# DDR16SS_DDR16SS_CTLPHY_WRAP_CTL_CFG_CTLCFG_0F308000h register map
Vendor: Texas Instruments
Registers are 32-bit, read-write, reset 0x0 unless marked. A register's access mark holds for its fields unless they carry their own. Offsets are as the file gives them; [hi:lo] are bit positions; lines under a group give offsets from that group; {n}, {i} and the like mark numbered series.

## DDR16SS_CTLPHY_WRAP_CTL_CFG_CTLCFG (part 7 of 11)
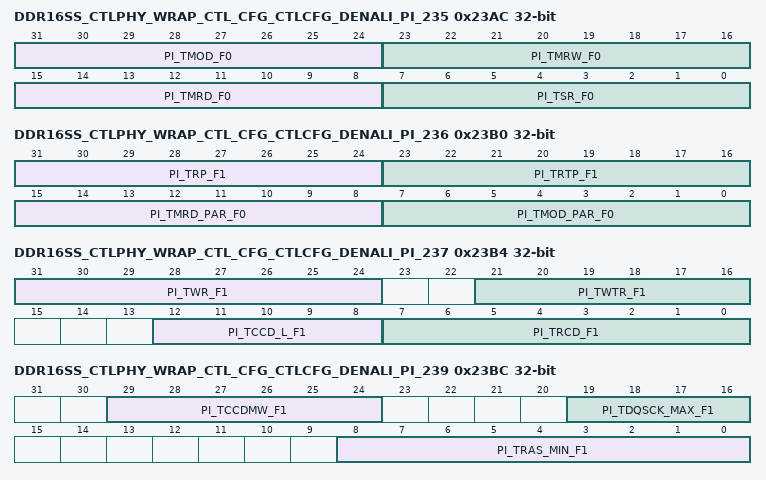
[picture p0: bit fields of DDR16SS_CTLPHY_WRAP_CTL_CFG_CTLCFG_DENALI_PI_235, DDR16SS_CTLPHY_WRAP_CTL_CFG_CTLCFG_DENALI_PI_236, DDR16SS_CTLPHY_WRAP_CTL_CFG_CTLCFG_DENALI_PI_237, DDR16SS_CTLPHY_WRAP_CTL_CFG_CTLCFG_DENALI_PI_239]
0x23AC DDR16SS_CTLPHY_WRAP_CTL_CFG_CTLCFG_DENALI_PI_235
  [31:24] PI_TMOD_F0 — DRAM tMOD value in cycles for frequency set 0. Reset Source: ctl_amod_g_rst_n
  [23:16] PI_TMRW_F0 — DRAM tMRW value in cycles for frequency set 0. Reset Source: ctl_amod_g_rst_n
  [15:8] PI_TMRD_F0 — DRAM tMRD value in cycles for frequency set 0. Reset Source: ctl_amod_g_rst_n
  [7:0] PI_TSR_F0 — Min cycles from sref entry to sref exit for frequency set 0. Reset Source: ctl_amod_g_rst_n
0x23B0 DDR16SS_CTLPHY_WRAP_CTL_CFG_CTLCFG_DENALI_PI_236
  [31:24] PI_TRP_F1 — DRAM tRP value in cycles for frequency set 1. Reset Source: ctl_amod_g_rst_n
  [23:16] PI_TRTP_F1 — DRAM tRTP value in cycles for frequency set 1. Reset Source: ctl_amod_g_rst_n
  [15:8] PI_TMRD_PAR_F0 — DRAM tMRD value when CA parity is enabled in cycles for frequency set 0. Reset Source: ctl_amod_g_rst_n
  [7:0] PI_TMOD_PAR_F0 — DRAM tMOD value when CA parity is enabled in cycles for frequency set 0. Reset Source: ctl_amod_g_rst_n
0x23B4 DDR16SS_CTLPHY_WRAP_CTL_CFG_CTLCFG_DENALI_PI_237
  [31:24] PI_TWR_F1 — DRAM tWR value in cycles for frequency set 1. Reset Source: ctl_amod_g_rst_n
  [21:16] PI_TWTR_F1 — DRAM tWTR value in cycles for frequency set 1. Reset Source: ctl_amod_g_rst_n
  [12:8] PI_TCCD_L_F1 — DRAM CAS-to_CAS value within the same bank group in cycles for frequency set 1. Reset Source: ctl_amod_g_rst_n
  [7:0] PI_TRCD_F1 — DRAM tRCD value in cycles for frequency set 1. Reset Source: ctl_amod_g_rst_n
0x23B8 DDR16SS_CTLPHY_WRAP_CTL_CFG_CTLCFG_DENALI_PI_238
  [19:0] PI_TRAS_MAX_F1 — DRAM tRAS_MAX value in cycles for frequency set 1. Reset Source: ctl_amod_g_rst_n
0x23BC DDR16SS_CTLPHY_WRAP_CTL_CFG_CTLCFG_DENALI_PI_239
  [29:24] PI_TCCDMW_F1 — LPDDR4 DRAM tCCDMW in cycles for frequency set 1. Reset Source: ctl_amod_g_rst_n
  [19:16] PI_TDQSCK_MAX_F1 — Additional delay needed for tDQSCK for frequency set 1. Reset Source: ctl_amod_g_rst_n
  [8:0] PI_TRAS_MIN_F1 — DRAM tRAS_MIN value in cycles for frequency set 1. Reset Source: ctl_amod_g_rst_n
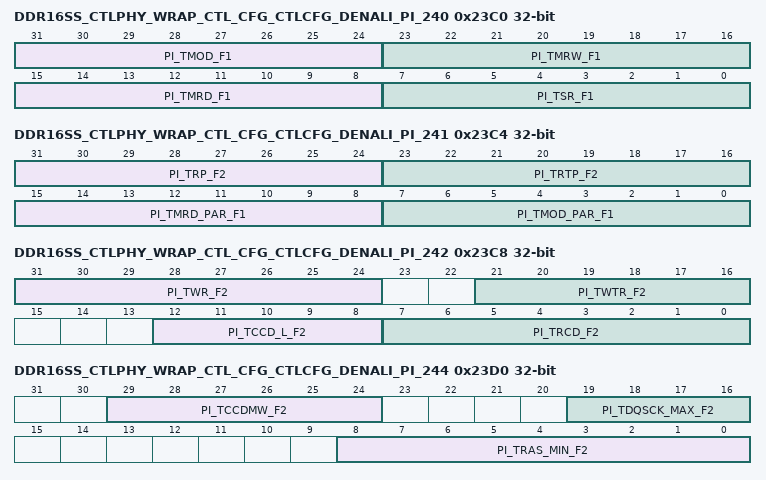
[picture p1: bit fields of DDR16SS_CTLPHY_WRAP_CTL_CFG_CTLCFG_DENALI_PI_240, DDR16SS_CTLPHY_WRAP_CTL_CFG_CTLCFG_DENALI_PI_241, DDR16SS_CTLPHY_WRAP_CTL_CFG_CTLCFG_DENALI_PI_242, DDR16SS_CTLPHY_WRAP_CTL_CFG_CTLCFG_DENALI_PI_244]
0x23C0 DDR16SS_CTLPHY_WRAP_CTL_CFG_CTLCFG_DENALI_PI_240
  [31:24] PI_TMOD_F1 — DRAM tMOD value in cycles for frequency set 1. Reset Source: ctl_amod_g_rst_n
  [23:16] PI_TMRW_F1 — DRAM tMRW value in cycles for frequency set 1. Reset Source: ctl_amod_g_rst_n
  [15:8] PI_TMRD_F1 — DRAM tMRD value in cycles for frequency set 1. Reset Source: ctl_amod_g_rst_n
  [7:0] PI_TSR_F1 — Min cycles from sref entry to sref exit for frequency set 1. Reset Source: ctl_amod_g_rst_n
0x23C4 DDR16SS_CTLPHY_WRAP_CTL_CFG_CTLCFG_DENALI_PI_241
  [31:24] PI_TRP_F2 — DRAM tRP value in cycles for frequency set 2. Reset Source: ctl_amod_g_rst_n
  [23:16] PI_TRTP_F2 — DRAM tRTP value in cycles for frequency set 2. Reset Source: ctl_amod_g_rst_n
  [15:8] PI_TMRD_PAR_F1 — DRAM tMRD value when CA parity is enabled in cycles for frequency set 1. Reset Source: ctl_amod_g_rst_n
  [7:0] PI_TMOD_PAR_F1 — DRAM tMOD value when CA parity is enabled in cycles for frequency set 1. Reset Source: ctl_amod_g_rst_n
0x23C8 DDR16SS_CTLPHY_WRAP_CTL_CFG_CTLCFG_DENALI_PI_242
  [31:24] PI_TWR_F2 — DRAM tWR value in cycles for frequency set 2. Reset Source: ctl_amod_g_rst_n
  [21:16] PI_TWTR_F2 — DRAM tWTR value in cycles for frequency set 2. Reset Source: ctl_amod_g_rst_n
  [12:8] PI_TCCD_L_F2 — DRAM CAS-to_CAS value within the same bank group in cycles for frequency set 2. Reset Source: ctl_amod_g_rst_n
  [7:0] PI_TRCD_F2 — DRAM tRCD value in cycles for frequency set 2. Reset Source: ctl_amod_g_rst_n
0x23CC DDR16SS_CTLPHY_WRAP_CTL_CFG_CTLCFG_DENALI_PI_243
  [19:0] PI_TRAS_MAX_F2 — DRAM tRAS_MAX value in cycles for frequency set 2. Reset Source: ctl_amod_g_rst_n
0x23D0 DDR16SS_CTLPHY_WRAP_CTL_CFG_CTLCFG_DENALI_PI_244
  [29:24] PI_TCCDMW_F2 — LPDDR4 DRAM tCCDMW in cycles for frequency set 2. Reset Source: ctl_amod_g_rst_n
  [19:16] PI_TDQSCK_MAX_F2 — Additional delay needed for tDQSCK for frequency set 2. Reset Source: ctl_amod_g_rst_n
  [8:0] PI_TRAS_MIN_F2 — DRAM tRAS_MIN value in cycles for frequency set 2. Reset Source: ctl_amod_g_rst_n
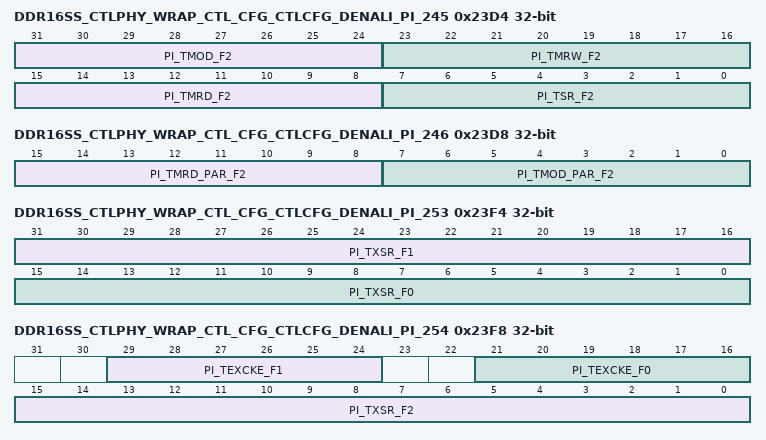
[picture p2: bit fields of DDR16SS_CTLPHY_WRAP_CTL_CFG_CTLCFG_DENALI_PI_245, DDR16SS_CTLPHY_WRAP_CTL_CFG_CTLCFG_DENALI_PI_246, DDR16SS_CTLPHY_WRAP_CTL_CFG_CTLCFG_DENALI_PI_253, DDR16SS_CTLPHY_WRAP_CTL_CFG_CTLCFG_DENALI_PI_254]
0x23D4 DDR16SS_CTLPHY_WRAP_CTL_CFG_CTLCFG_DENALI_PI_245
  [31:24] PI_TMOD_F2 — DRAM tMOD value in cycles for frequency set 2. Reset Source: ctl_amod_g_rst_n
  [23:16] PI_TMRW_F2 — DRAM tMRW value in cycles for frequency set 2. Reset Source: ctl_amod_g_rst_n
  [15:8] PI_TMRD_F2 — DRAM tMRD value in cycles for frequency set 2. Reset Source: ctl_amod_g_rst_n
  [7:0] PI_TSR_F2 — Min cycles from sref entry to sref exit for frequency set 2. Reset Source: ctl_amod_g_rst_n
0x23D8 DDR16SS_CTLPHY_WRAP_CTL_CFG_CTLCFG_DENALI_PI_246
  [15:8] PI_TMRD_PAR_F2 — DRAM tMRD value when CA parity is enabled in cycles for frequency set 2. Reset Source: ctl_amod_g_rst_n
  [7:0] PI_TMOD_PAR_F2 — DRAM tMOD value when CA parity is enabled in cycles for frequency set 2. Reset Source: ctl_amod_g_rst_n
0x23DC DDR16SS_CTLPHY_WRAP_CTL_CFG_CTLCFG_DENALI_PI_247
  [20:0] PI_TDFI_CTRLUPD_MAX_F0 — Defines the DFI tCTRLUPD_MAX timing parameter [in DFI clocks] for frequency set 0, the maximum cycles that dfi_ctrlupd_req can be asserted. If programmed to a non-zero, a timing violation will cause an interrupt and bit [1] set in the PI_UPDATE_ERROR_STATUS parameter. Reset Source: ctl_amod_g_rst_n
0x23E0 DDR16SS_CTLPHY_WRAP_CTL_CFG_CTLCFG_DENALI_PI_248
  [31:0] PI_TDFI_CTRLUPD_INTERVAL_F0 — Defines the DFI tCTRLUPD_INTERVAL timing parameter [in DFI clocks] for frequency set 0, the maximum cycles between dfi_ctrlupd_req assertions. If programmed to a non-zero, a timing violation will cause an interrupt and bit [0] set in the PI_UPDATE_ERROR_STATUS parameter. Reset Source: ctl_amod_g_rst_n
0x23E4 DDR16SS_CTLPHY_WRAP_CTL_CFG_CTLCFG_DENALI_PI_249
  [20:0] PI_TDFI_CTRLUPD_MAX_F1 — Defines the DFI tCTRLUPD_MAX timing parameter [in DFI clocks] for frequency set 1, the maximum cycles that dfi_ctrlupd_req can be asserted. If programmed to a non-zero, a timing violation will cause an interrupt and bit [1] set in the PI_UPDATE_ERROR_STATUS parameter. Reset Source: ctl_amod_g_rst_n
0x23E8 DDR16SS_CTLPHY_WRAP_CTL_CFG_CTLCFG_DENALI_PI_250
  [31:0] PI_TDFI_CTRLUPD_INTERVAL_F1 — Defines the DFI tCTRLUPD_INTERVAL timing parameter [in DFI clocks] for frequency set 1, the maximum cycles between dfi_ctrlupd_req assertions. If programmed to a non-zero, a timing violation will cause an interrupt and bit [0] set in the PI_UPDATE_ERROR_STATUS parameter. Reset Source: ctl_amod_g_rst_n
0x23EC DDR16SS_CTLPHY_WRAP_CTL_CFG_CTLCFG_DENALI_PI_251
  [20:0] PI_TDFI_CTRLUPD_MAX_F2 — Defines the DFI tCTRLUPD_MAX timing parameter [in DFI clocks] for frequency set 2, the maximum cycles that dfi_ctrlupd_req can be asserted. If programmed to a non-zero, a timing violation will cause an interrupt and bit [1] set in the PI_UPDATE_ERROR_STATUS parameter. Reset Source: ctl_amod_g_rst_n
0x23F0 DDR16SS_CTLPHY_WRAP_CTL_CFG_CTLCFG_DENALI_PI_252
  [31:0] PI_TDFI_CTRLUPD_INTERVAL_F2 — Defines the DFI tCTRLUPD_INTERVAL timing parameter [in DFI clocks] for frequency set 2, the maximum cycles between dfi_ctrlupd_req assertions. If programmed to a non-zero, a timing violation will cause an interrupt and bit [0] set in the PI_UPDATE_ERROR_STATUS parameter. Reset Source: ctl_amod_g_rst_n
0x23F4 DDR16SS_CTLPHY_WRAP_CTL_CFG_CTLCFG_DENALI_PI_253
  [31:16] PI_TXSR_F1 — DRAM TXSR value for frequency set 1 in cycles. Reset Source: ctl_amod_g_rst_n
  [15:0] PI_TXSR_F0 — DRAM TXSR value for frequency set 0 in cycles. Reset Source: ctl_amod_g_rst_n
0x23F8 DDR16SS_CTLPHY_WRAP_CTL_CFG_CTLCFG_DENALI_PI_254
  [29:24] PI_TEXCKE_F1 — DRAM CKE low after SREF command timing for frequency set 1. Reset Source: ctl_amod_g_rst_n
  [21:16] PI_TEXCKE_F0 — DRAM CKE low after SREF command timing for frequency set 0. Reset Source: ctl_amod_g_rst_n
  [15:0] PI_TXSR_F2 — DRAM TXSR value for frequency set 2 in cycles. Reset Source: ctl_amod_g_rst_n
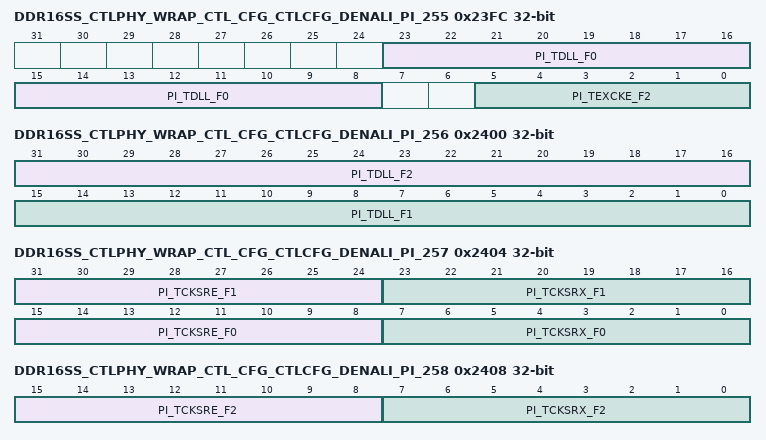
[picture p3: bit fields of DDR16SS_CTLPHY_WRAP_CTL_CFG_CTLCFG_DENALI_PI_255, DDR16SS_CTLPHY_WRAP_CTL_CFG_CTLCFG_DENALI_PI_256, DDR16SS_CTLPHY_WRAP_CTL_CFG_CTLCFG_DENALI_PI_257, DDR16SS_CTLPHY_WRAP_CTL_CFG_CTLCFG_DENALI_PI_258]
0x23FC DDR16SS_CTLPHY_WRAP_CTL_CFG_CTLCFG_DENALI_PI_255
  [23:8] PI_TDLL_F0 — DRAM tDLL value for frequency set 0 in cycles. Reset Source: ctl_amod_g_rst_n
  [5:0] PI_TEXCKE_F2 — DRAM CKE low after SREF command timing for frequency set 2. Reset Source: ctl_amod_g_rst_n
0x2400 DDR16SS_CTLPHY_WRAP_CTL_CFG_CTLCFG_DENALI_PI_256
  [31:16] PI_TDLL_F2 — DRAM tDLL value for frequency set 2 in cycles. Reset Source: ctl_amod_g_rst_n
  [15:0] PI_TDLL_F1 — DRAM tDLL value for frequency set 1 in cycles. Reset Source: ctl_amod_g_rst_n
0x2404 DDR16SS_CTLPHY_WRAP_CTL_CFG_CTLCFG_DENALI_PI_257
  [31:24] PI_TCKSRE_F1 — DRAM tCKSRE value. Reset Source: ctl_amod_g_rst_n
  [23:16] PI_TCKSRX_F1 — DRAM tCKSRX value. Reset Source: ctl_amod_g_rst_n
  [15:8] PI_TCKSRE_F0 — DRAM tCKSRE value. Reset Source: ctl_amod_g_rst_n
  [7:0] PI_TCKSRX_F0 — DRAM tCKSRX value. Reset Source: ctl_amod_g_rst_n
0x2408 DDR16SS_CTLPHY_WRAP_CTL_CFG_CTLCFG_DENALI_PI_258
  [15:8] PI_TCKSRE_F2 — DRAM tCKSRE value. Reset Source: ctl_amod_g_rst_n
  [7:0] PI_TCKSRX_F2 — DRAM tCKSRX value. Reset Source: ctl_amod_g_rst_n
0x240C DDR16SS_CTLPHY_WRAP_CTL_CFG_CTLCFG_DENALI_PI_259
  [23:0] PI_TINIT_F0 — DRAM tINIT value for frequency set 0 in cycles. Reset Source: ctl_amod_g_rst_n
{0x2000+4i} DDR16SS_CTLPHY_WRAP_CTL_CFG_CTLCFG_DENALI_PI_{i} (i=260..262)
  [23:0] PI_TINIT{i-257}_F0 — DRAM tINIT{i-257} value for frequency set 0 in cycles. Reset Source: ctl_amod_g_rst_n
0x241C DDR16SS_CTLPHY_WRAP_CTL_CFG_CTLCFG_DENALI_PI_263
  [15:0] PI_TXSNR_F0 — DRAM tXSNR value for frequency set 0 in cycles. Reset Source: ctl_amod_g_rst_n
0x2420 DDR16SS_CTLPHY_WRAP_CTL_CFG_CTLCFG_DENALI_PI_264
  [23:0] PI_TINIT_F1 — DRAM tINIT value for frequency set 1 in cycles. Reset Source: ctl_amod_g_rst_n
{0x2000+4i} DDR16SS_CTLPHY_WRAP_CTL_CFG_CTLCFG_DENALI_PI_{i} (i=265..267)
  [23:0] PI_TINIT{i-262}_F1 — DRAM tINIT{i-262} value for frequency set 1 in cycles. Reset Source: ctl_amod_g_rst_n
0x2430 DDR16SS_CTLPHY_WRAP_CTL_CFG_CTLCFG_DENALI_PI_268
  [15:0] PI_TXSNR_F1 — DRAM tXSNR value for frequency set 1 in cycles. Reset Source: ctl_amod_g_rst_n
0x2434 DDR16SS_CTLPHY_WRAP_CTL_CFG_CTLCFG_DENALI_PI_269
  [23:0] PI_TINIT_F2 — DRAM tINIT value for frequency set 2 in cycles. Reset Source: ctl_amod_g_rst_n
{0x2000+4i} DDR16SS_CTLPHY_WRAP_CTL_CFG_CTLCFG_DENALI_PI_{i} (i=270..272)
  [23:0] PI_TINIT{i-267}_F2 — DRAM tINIT{i-267} value for frequency set 2 in cycles. Reset Source: ctl_amod_g_rst_n
0x2444 DDR16SS_CTLPHY_WRAP_CTL_CFG_CTLCFG_DENALI_PI_273
  [15:0] PI_TXSNR_F2 — DRAM tXSNR value for frequency set 2 in cycles. Reset Source: ctl_amod_g_rst_n
0x2448 DDR16SS_CTLPHY_WRAP_CTL_CFG_CTLCFG_DENALI_PI_274
  [27:16] PI_TZQCAL_F0 — Holds the DRAM ZQCAL value for frequency set 0 in cycles. Reset Source: ctl_amod_g_rst_n
0x244C DDR16SS_CTLPHY_WRAP_CTL_CFG_CTLCFG_DENALI_PI_275
  [6:0] PI_TZQLAT_F0 — Holds the DRAM ZQLAT value for frequency set 0 in cycles. Reset Source: ctl_amod_g_rst_n
0x2450 DDR16SS_CTLPHY_WRAP_CTL_CFG_CTLCFG_DENALI_PI_276
  [27:16] PI_TZQCAL_F1 — Holds the DRAM ZQCAL value for frequency set 1 in cycles. Reset Source: ctl_amod_g_rst_n
0x2454 DDR16SS_CTLPHY_WRAP_CTL_CFG_CTLCFG_DENALI_PI_277
  [6:0] PI_TZQLAT_F1 — Holds the DRAM ZQLAT value for frequency set 1 in cycles. Reset Source: ctl_amod_g_rst_n
0x2458 DDR16SS_CTLPHY_WRAP_CTL_CFG_CTLCFG_DENALI_PI_278
  [27:16] PI_TZQCAL_F2 — Holds the DRAM ZQCAL value for frequency set 2 in cycles. Reset Source: ctl_amod_g_rst_n
0x245C DDR16SS_CTLPHY_WRAP_CTL_CFG_CTLCFG_DENALI_PI_279
  [6:0] PI_TZQLAT_F2 — Holds the DRAM ZQLAT value for frequency set 2 in cycles. Reset Source: ctl_amod_g_rst_n
0x2460 DDR16SS_CTLPHY_WRAP_CTL_CFG_CTLCFG_DENALI_PI_280 access not given reset not defined
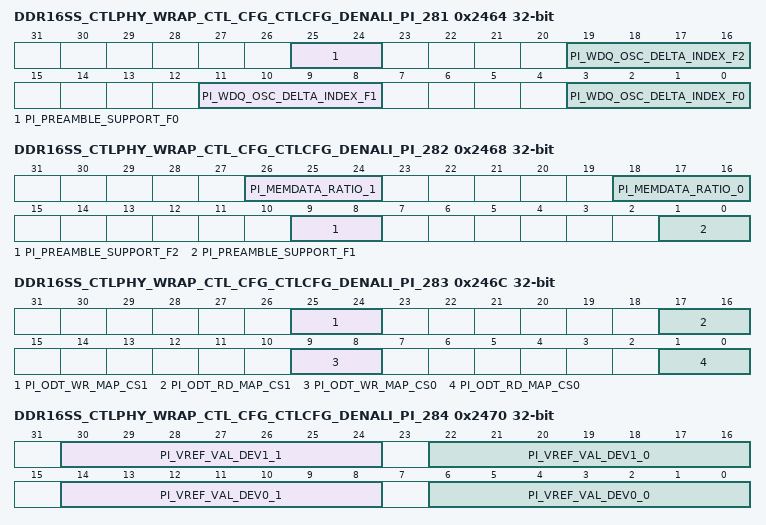
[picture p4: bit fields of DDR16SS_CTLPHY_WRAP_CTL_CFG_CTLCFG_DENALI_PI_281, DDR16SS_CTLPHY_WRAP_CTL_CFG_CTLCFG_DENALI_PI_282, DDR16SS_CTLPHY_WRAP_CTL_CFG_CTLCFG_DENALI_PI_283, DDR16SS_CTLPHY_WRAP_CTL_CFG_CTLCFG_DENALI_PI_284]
0x2464 DDR16SS_CTLPHY_WRAP_CTL_CFG_CTLCFG_DENALI_PI_281
  [25:24] PI_PREAMBLE_SUPPORT_F0 — bit0: Selection of one or two cycle preamble for read burst transfers. bit1: Selection of one or two cycles write burst transfers for NON-DDR5,one or multi[up to four] cycles write burst transfers for DDR5. Reset Source: ctl_amod_g_rst_n
  [19:16] PI_WDQ_OSC_DELTA_INDEX_F2 — WDQ DQS delay delta index for OSC triggered periodic training for frequency set 2. If the value is n, the delay is 2^n/512 cycle. Reset Source: ctl_amod_g_rst_n
  [11:8] PI_WDQ_OSC_DELTA_INDEX_F1 — WDQ DQS delay delta index for OSC triggered periodic training for frequency set 1. If the value is n, the delay is 2^n/512 cycle. Reset Source: ctl_amod_g_rst_n
  [3:0] PI_WDQ_OSC_DELTA_INDEX_F0 — WDQ DQS delay delta index for OSC triggered periodic training for frequency set 0. If the value is n, the delay is 2^n/512 cycle. Reset Source: ctl_amod_g_rst_n
0x2468 DDR16SS_CTLPHY_WRAP_CTL_CFG_CTLCFG_DENALI_PI_282
  [26:24] PI_MEMDATA_RATIO_1 — Defines the ratio of the DRAM device size on chip select 1 to the memory data width. Program with the log2 ratio of the memory data width to the device data width. Reset Source: ctl_amod_g_rst_n
  [18:16] PI_MEMDATA_RATIO_0 — Defines the ratio of the DRAM device size on chip select 0 to the memory data width. Program with the log2 ratio of the memory data width to the device data width. Reset Source: ctl_amod_g_rst_n
  [9:8] PI_PREAMBLE_SUPPORT_F2 — bit0: Selection of one or two cycle preamble for read burst transfers. bit1: Selection of one or two cycles write burst transfers for NON-DDR5,one or multi[up to four] cycles write burst transfers for DDR5. Reset Source: ctl_amod_g_rst_n
  [1:0] PI_PREAMBLE_SUPPORT_F1 — bit0: Selection of one or two cycle preamble for read burst transfers. bit1: Selection of one or two cycles write burst transfers for NON-DDR5,one or multi[up to four] cycles write burst transfers for DDR5. Reset Source: ctl_amod_g_rst_n
0x246C DDR16SS_CTLPHY_WRAP_CTL_CFG_CTLCFG_DENALI_PI_283
  [25:24] PI_ODT_WR_MAP_CS1 — Determines which chip[s] will have termination when a write occurs on chip select 1. Set bit X to enable termination on csX when cs1 is performing a write. Reset Source: ctl_amod_g_rst_n
  [17:16] PI_ODT_RD_MAP_CS1 — Determines which chip[s] will have termination when a read occurs on chip select 1. Set bit X to enable termination on csX when cs1 is performing a read. Reset Source: ctl_amod_g_rst_n
  [9:8] PI_ODT_WR_MAP_CS0 — Determines which chip[s] will have termination when a write occurs on chip select 0. Set bit X to enable termination on csX when cs0 is performing a write. Reset Source: ctl_amod_g_rst_n
  [1:0] PI_ODT_RD_MAP_CS0 — Determines which chip[s] will have termination when a read occurs on chip select 0. Set bit X to enable termination on csX when cs0 is performing a read. Reset Source: ctl_amod_g_rst_n
0x2470 DDR16SS_CTLPHY_WRAP_CTL_CFG_CTLCFG_DENALI_PI_284
  [30:24] PI_VREF_VAL_DEV1_1 — Defines the range and value for VREF training for DRAM 1 for CS 1. If the PI_VREF_PDA_EN parameter is not set, device 0 values are used for all devices. Reset Source: ctl_amod_g_rst_n
  [22:16] PI_VREF_VAL_DEV1_0 — Defines the range and value for VREF training for DRAM 1 for CS 0. If the PI_VREF_PDA_EN parameter is not set, device 0 values are used for all devices. Reset Source: ctl_amod_g_rst_n
  [14:8] PI_VREF_VAL_DEV0_1 — Defines the range and value for VREF training for DRAM 0 for CS 1. If the PI_VREF_PDA_EN parameter is not set, device 0 values are used for all devices. Reset Source: ctl_amod_g_rst_n
  [6:0] PI_VREF_VAL_DEV0_0 — Defines the range and value for VREF training for DRAM 0 for CS 0. If the PI_VREF_PDA_EN parameter is not set, device 0 values are used for all devices. Reset Source: ctl_amod_g_rst_n
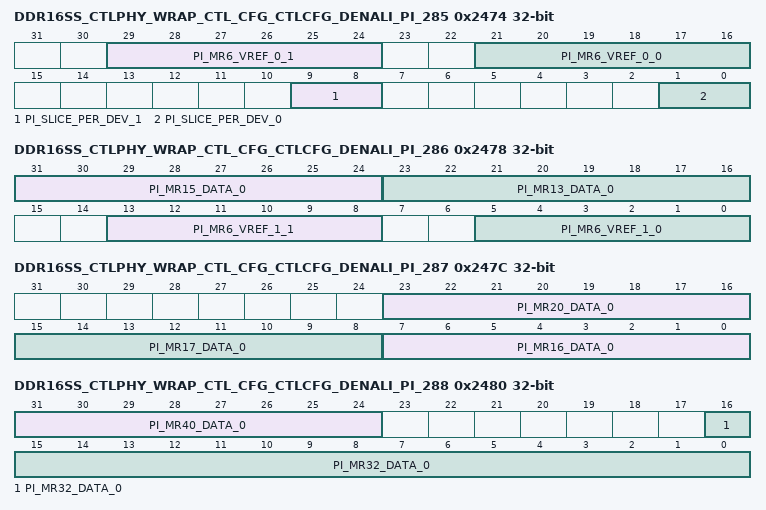
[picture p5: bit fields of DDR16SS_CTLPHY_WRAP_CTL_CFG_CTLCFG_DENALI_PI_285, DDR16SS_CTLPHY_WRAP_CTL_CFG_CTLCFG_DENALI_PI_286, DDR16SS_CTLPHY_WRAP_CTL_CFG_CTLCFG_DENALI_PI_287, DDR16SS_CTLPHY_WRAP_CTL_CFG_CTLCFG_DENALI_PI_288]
0x2474 DDR16SS_CTLPHY_WRAP_CTL_CFG_CTLCFG_DENALI_PI_285 access per field
  [29:24] PI_MR6_VREF_0_1 ro — The parameter stores the vref value of every devices of the same CS. It is updated after WDQLVL PDA mode completed. READ-ONLY. Reset Source: ctl_amod_g_rst_n
  [21:16] PI_MR6_VREF_0_0 ro — The parameter stores the vref value of every devices of the same CS. It is updated after WDQLVL PDA mode completed. READ-ONLY. Reset Source: ctl_amod_g_rst_n
  [9:8] PI_SLICE_PER_DEV_1 rw — Indicates the number of data slices per memory device. The device width divided by 8. Reset Source: ctl_amod_g_rst_n
  [1:0] PI_SLICE_PER_DEV_0 rw — Indicates the number of data slices per memory device. The device width divided by 8. Reset Source: ctl_amod_g_rst_n
0x2478 DDR16SS_CTLPHY_WRAP_CTL_CFG_CTLCFG_DENALI_PI_286 access per field
  [31:24] PI_MR15_DATA_0 rw — Data to program into memory mode register 15 for chip select 0. Reset Source: ctl_amod_g_rst_n
  [23:16] PI_MR13_DATA_0 rw — Data to program into memory mode register 13 for chip select 0. Reset Source: ctl_amod_g_rst_n
  [13:8] PI_MR6_VREF_1_1 ro — The parameter stores the vref value of every devices of the same CS. It is updated after WDQLVL PDA mode completed. READ-ONLY. Reset Source: ctl_amod_g_rst_n
  [5:0] PI_MR6_VREF_1_0 ro — The parameter stores the vref value of every devices of the same CS. It is updated after WDQLVL PDA mode completed. READ-ONLY. Reset Source: ctl_amod_g_rst_n
0x247C DDR16SS_CTLPHY_WRAP_CTL_CFG_CTLCFG_DENALI_PI_287
  [23:16] PI_MR20_DATA_0 — Data to program into memory mode register 20 for chip select 0. Reset Source: ctl_amod_g_rst_n
  [15:8] PI_MR17_DATA_0 — Data to program into memory mode register 17 for chip select 0. Reset Source: ctl_amod_g_rst_n
  [7:0] PI_MR16_DATA_0 — Data to program into memory mode register 16 for chip select 0. Reset Source: ctl_amod_g_rst_n
0x2480 DDR16SS_CTLPHY_WRAP_CTL_CFG_CTLCFG_DENALI_PI_288
  [31:24] PI_MR40_DATA_0 — Data to program into memory mode register 40 for chip select 0. Reset Source: ctl_amod_g_rst_n
  [16:0] PI_MR32_DATA_0 — Data to program into memory mode register 32 for chip select 0. Reset Source: ctl_amod_g_rst_n
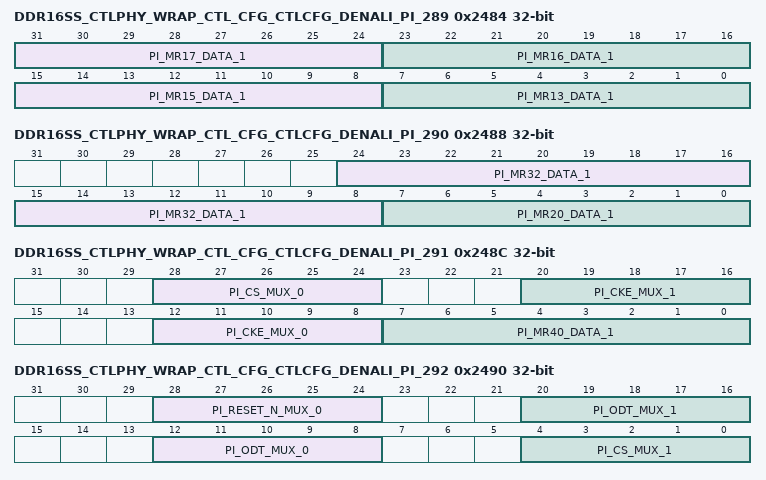
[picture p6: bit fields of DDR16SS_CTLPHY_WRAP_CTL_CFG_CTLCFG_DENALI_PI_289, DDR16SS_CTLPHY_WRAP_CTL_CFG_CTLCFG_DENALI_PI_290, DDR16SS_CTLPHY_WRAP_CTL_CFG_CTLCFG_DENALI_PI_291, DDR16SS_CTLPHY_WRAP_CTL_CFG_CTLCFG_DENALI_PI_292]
0x2484 DDR16SS_CTLPHY_WRAP_CTL_CFG_CTLCFG_DENALI_PI_289
  [31:24] PI_MR17_DATA_1 — Data to program into memory mode register 17 for chip select 1. Reset Source: ctl_amod_g_rst_n
  [23:16] PI_MR16_DATA_1 — Data to program into memory mode register 16 for chip select 1. Reset Source: ctl_amod_g_rst_n
  [15:8] PI_MR15_DATA_1 — Data to program into memory mode register 15 for chip select 1. Reset Source: ctl_amod_g_rst_n
  [7:0] PI_MR13_DATA_1 — Data to program into memory mode register 13 for chip select 1. Reset Source: ctl_amod_g_rst_n
0x2488 DDR16SS_CTLPHY_WRAP_CTL_CFG_CTLCFG_DENALI_PI_290
  [24:8] PI_MR32_DATA_1 — Data to program into memory mode register 32 for chip select 1. Reset Source: ctl_amod_g_rst_n
  [7:0] PI_MR20_DATA_1 — Data to program into memory mode register 20 for chip select 1. Reset Source: ctl_amod_g_rst_n
0x248C DDR16SS_CTLPHY_WRAP_CTL_CFG_CTLCFG_DENALI_PI_291
  [28:24] PI_CS_MUX_0 — Command pin CS_0 mux selector Reset Source: ctl_amod_g_rst_n
  [20:16] PI_CKE_MUX_1 — Command pin CKE_1 mux selector Reset Source: ctl_amod_g_rst_n
  [12:8] PI_CKE_MUX_0 — Command pin CKE_0 mux selector Reset Source: ctl_amod_g_rst_n
  [7:0] PI_MR40_DATA_1 — Data to program into memory mode register 40 for chip select 1. Reset Source: ctl_amod_g_rst_n
0x2490 DDR16SS_CTLPHY_WRAP_CTL_CFG_CTLCFG_DENALI_PI_292
  [28:24] PI_RESET_N_MUX_0 — Command pin RESET_N_0 mux selector Reset Source: ctl_amod_g_rst_n
  [20:16] PI_ODT_MUX_1 — Command pin ODT_1 mux selector Reset Source: ctl_amod_g_rst_n
  [12:8] PI_ODT_MUX_0 — Command pin ODT_0 mux selector Reset Source: ctl_amod_g_rst_n
  [4:0] PI_CS_MUX_1 — Command pin CS_1 mux selector Reset Source: ctl_amod_g_rst_n
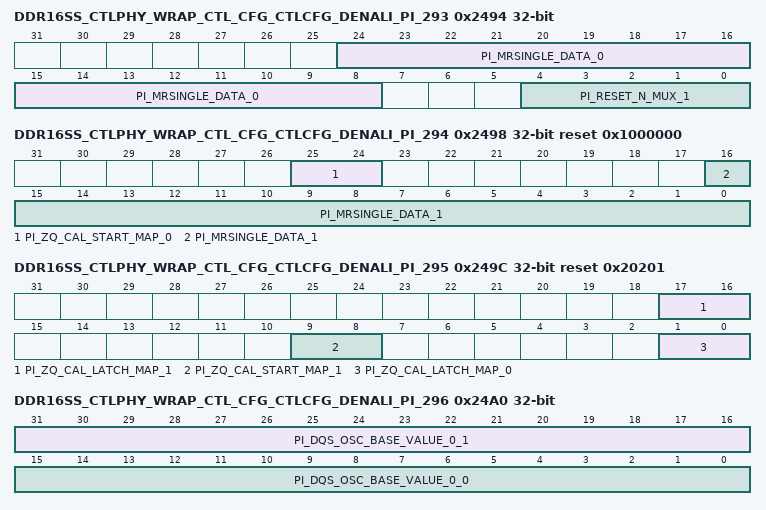
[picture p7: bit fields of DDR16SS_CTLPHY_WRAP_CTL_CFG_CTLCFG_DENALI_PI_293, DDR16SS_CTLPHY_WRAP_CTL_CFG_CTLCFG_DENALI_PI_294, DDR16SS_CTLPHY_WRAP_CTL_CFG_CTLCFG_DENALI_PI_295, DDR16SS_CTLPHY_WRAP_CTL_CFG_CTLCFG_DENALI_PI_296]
0x2494 DDR16SS_CTLPHY_WRAP_CTL_CFG_CTLCFG_DENALI_PI_293
  [24:8] PI_MRSINGLE_DATA_0 — Data to program into memory mode register single write to chip select 0. Reset Source: ctl_amod_g_rst_n
  [4:0] PI_RESET_N_MUX_1 — Command pin RESET_N_1 mux selector Reset Source: ctl_amod_g_rst_n
0x2498 DDR16SS_CTLPHY_WRAP_CTL_CFG_CTLCFG_DENALI_PI_294 reset 0x1000000
  [25:24] PI_ZQ_CAL_START_MAP_0 — Defines which chip select[s] will receive ZQ calibration start commands simultaneously on iteration 0 of the ZQ START initialization and periodic command sequences. Clear to all zeros for no ZQ START commands. Reset Source: ctl_amod_g_rst_n
  [16:0] PI_MRSINGLE_DATA_1 — Data to program into memory mode register single write to chip select 1. Reset Source: ctl_amod_g_rst_n
0x249C DDR16SS_CTLPHY_WRAP_CTL_CFG_CTLCFG_DENALI_PI_295 reset 0x20201
  [17:16] PI_ZQ_CAL_LATCH_MAP_1 — Defines which chip select[s] will receive ZQ calibration latch commands simultaneously on iteration 1 of the ZQ LATCH initialization and periodic command sequences. Clear to all zeros for no ZQ LATCH commands. Reset Source: ctl_amod_g_rst_n
  [9:8] PI_ZQ_CAL_START_MAP_1 — Defines which chip select[s] will receive ZQ calibration start commands simultaneously on iteration 1 of the ZQ START initialization and periodic command sequences. Clear to all zeros for no ZQ START commands. Reset Source: ctl_amod_g_rst_n
  [1:0] PI_ZQ_CAL_LATCH_MAP_0 — Defines which chip select[s] will receive ZQ calibration latch commands simultaneously on iteration 0 of the ZQ LATCH initialization and periodic command sequences. Clear to all zeros for no ZQ LATCH commands. Reset Source: ctl_amod_g_rst_n
0x24A0 DDR16SS_CTLPHY_WRAP_CTL_CFG_CTLCFG_DENALI_PI_296
  [31:16] PI_DQS_OSC_BASE_VALUE_0_1 — Base value for comparison of oscillator measurement for device 0 of rank 1 Reset Source: ctl_amod_g_rst_n
  [15:0] PI_DQS_OSC_BASE_VALUE_0_0 — Base value for comparison of oscillator measurement for device 0 of rank 0 Reset Source: ctl_amod_g_rst_n
{0x2000+4i} DDR16SS_CTLPHY_WRAP_CTL_CFG_CTLCFG_DENALI_PI_{i} (i=297..302)
  [16:0] PI_MR{i-297}_DATA_F0_0 — Data to program into memory mode register {i-297} for chip select 0 for frequency set 0. Reset Source: ctl_amod_g_rst_n
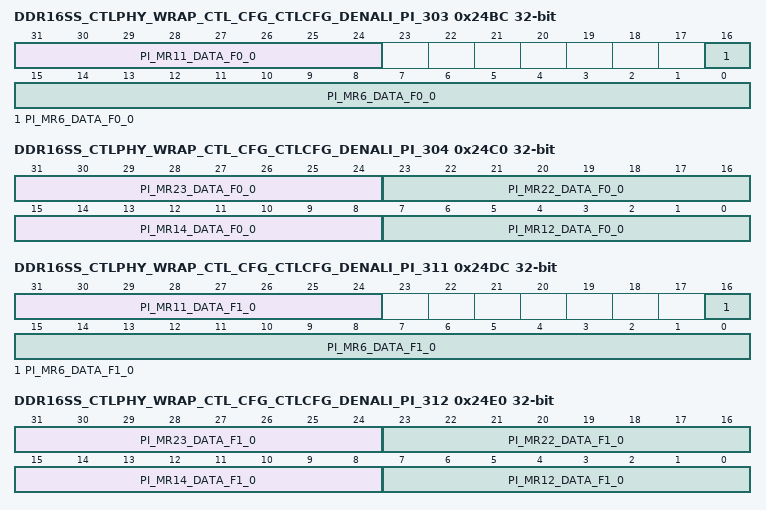
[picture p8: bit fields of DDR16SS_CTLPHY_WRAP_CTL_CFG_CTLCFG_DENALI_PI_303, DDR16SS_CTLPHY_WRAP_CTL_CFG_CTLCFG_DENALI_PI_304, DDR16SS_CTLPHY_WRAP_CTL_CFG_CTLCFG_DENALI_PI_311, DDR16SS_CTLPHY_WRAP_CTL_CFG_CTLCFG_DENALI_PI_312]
0x24BC DDR16SS_CTLPHY_WRAP_CTL_CFG_CTLCFG_DENALI_PI_303
  [31:24] PI_MR11_DATA_F0_0 — Data to program into memory mode register 11 for chip select 0 for frequency set 0. Reset Source: ctl_amod_g_rst_n
  [16:0] PI_MR6_DATA_F0_0 — Data to program into memory mode register 6 for chip select 0 for frequency set 0. Reset Source: ctl_amod_g_rst_n
0x24C0 DDR16SS_CTLPHY_WRAP_CTL_CFG_CTLCFG_DENALI_PI_304
  [31:24] PI_MR23_DATA_F0_0 — Data to program into memory mode register 23 for chip select 0 for frequency set 0. Reset Source: ctl_amod_g_rst_n
  [23:16] PI_MR22_DATA_F0_0 — Data to program into memory mode register 22 for chip select 0 for frequency set 0. Reset Source: ctl_amod_g_rst_n
  [15:8] PI_MR14_DATA_F0_0 — Data to program into memory mode register 14 for chip select 0 for frequency set 0. Reset Source: ctl_amod_g_rst_n
  [7:0] PI_MR12_DATA_F0_0 — Data to program into memory mode register 12 for chip select 0 for frequency set 0. Reset Source: ctl_amod_g_rst_n
{0x2000+4i} DDR16SS_CTLPHY_WRAP_CTL_CFG_CTLCFG_DENALI_PI_{i} (i=305..310)
  [16:0] PI_MR{i-305}_DATA_F1_0 — Data to program into memory mode register {i-305} for chip select 0 for frequency set 1. Reset Source: ctl_amod_g_rst_n
0x24DC DDR16SS_CTLPHY_WRAP_CTL_CFG_CTLCFG_DENALI_PI_311
  [31:24] PI_MR11_DATA_F1_0 — Data to program into memory mode register 11 for chip select 0 for frequency set 1. Reset Source: ctl_amod_g_rst_n
  [16:0] PI_MR6_DATA_F1_0 — Data to program into memory mode register 6 for chip select 0 for frequency set 1. Reset Source: ctl_amod_g_rst_n
0x24E0 DDR16SS_CTLPHY_WRAP_CTL_CFG_CTLCFG_DENALI_PI_312
  [31:24] PI_MR23_DATA_F1_0 — Data to program into memory mode register 23 for chip select 0 for frequency set 1. Reset Source: ctl_amod_g_rst_n
  [23:16] PI_MR22_DATA_F1_0 — Data to program into memory mode register 22 for chip select 0 for frequency set 1. Reset Source: ctl_amod_g_rst_n
  [15:8] PI_MR14_DATA_F1_0 — Data to program into memory mode register 14 for chip select 0 for frequency set 1. Reset Source: ctl_amod_g_rst_n
  [7:0] PI_MR12_DATA_F1_0 — Data to program into memory mode register 12 for chip select 0 for frequency set 1. Reset Source: ctl_amod_g_rst_n
{0x2000+4i} DDR16SS_CTLPHY_WRAP_CTL_CFG_CTLCFG_DENALI_PI_{i} (i=313..318)
  [16:0] PI_MR{i-313}_DATA_F2_0 — Data to program into memory mode register {i-313} for chip select 0 for frequency set 2. Reset Source: ctl_amod_g_rst_n
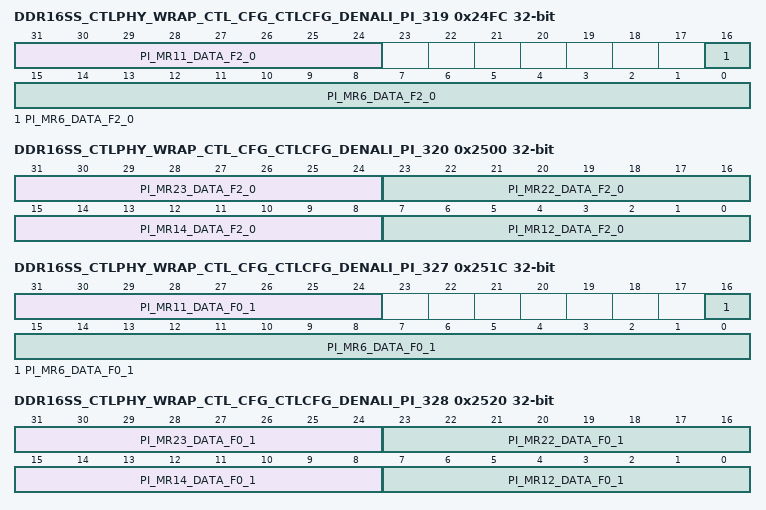
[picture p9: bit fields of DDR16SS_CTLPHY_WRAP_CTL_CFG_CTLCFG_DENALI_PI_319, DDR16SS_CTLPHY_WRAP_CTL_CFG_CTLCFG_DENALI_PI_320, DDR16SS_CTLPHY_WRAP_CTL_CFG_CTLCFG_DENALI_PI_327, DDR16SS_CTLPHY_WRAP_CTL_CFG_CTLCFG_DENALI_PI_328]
0x24FC DDR16SS_CTLPHY_WRAP_CTL_CFG_CTLCFG_DENALI_PI_319
  [31:24] PI_MR11_DATA_F2_0 — Data to program into memory mode register 11 for chip select 0 for frequency set 2. Reset Source: ctl_amod_g_rst_n
  [16:0] PI_MR6_DATA_F2_0 — Data to program into memory mode register 6 for chip select 0 for frequency set 2. Reset Source: ctl_amod_g_rst_n
0x2500 DDR16SS_CTLPHY_WRAP_CTL_CFG_CTLCFG_DENALI_PI_320
  [31:24] PI_MR23_DATA_F2_0 — Data to program into memory mode register 23 for chip select 0 for frequency set 2. Reset Source: ctl_amod_g_rst_n
  [23:16] PI_MR22_DATA_F2_0 — Data to program into memory mode register 22 for chip select 0 for frequency set 2. Reset Source: ctl_amod_g_rst_n
  [15:8] PI_MR14_DATA_F2_0 — Data to program into memory mode register 14 for chip select 0 for frequency set 2. Reset Source: ctl_amod_g_rst_n
  [7:0] PI_MR12_DATA_F2_0 — Data to program into memory mode register 12 for chip select 0 for frequency set 2. Reset Source: ctl_amod_g_rst_n
{0x2000+4i} DDR16SS_CTLPHY_WRAP_CTL_CFG_CTLCFG_DENALI_PI_{i} (i=321..326)
  [16:0] PI_MR{i-321}_DATA_F0_1 — Data to program into memory mode register {i-321} for chip select 1 for frequency set 0. Reset Source: ctl_amod_g_rst_n
0x251C DDR16SS_CTLPHY_WRAP_CTL_CFG_CTLCFG_DENALI_PI_327
  [31:24] PI_MR11_DATA_F0_1 — Data to program into memory mode register 11 for chip select 1 for frequency set 0. Reset Source: ctl_amod_g_rst_n
  [16:0] PI_MR6_DATA_F0_1 — Data to program into memory mode register 6 for chip select 1 for frequency set 0. Reset Source: ctl_amod_g_rst_n
0x2520 DDR16SS_CTLPHY_WRAP_CTL_CFG_CTLCFG_DENALI_PI_328
  [31:24] PI_MR23_DATA_F0_1 — Data to program into memory mode register 23 for chip select 1 for frequency set 0. Reset Source: ctl_amod_g_rst_n
  [23:16] PI_MR22_DATA_F0_1 — Data to program into memory mode register 22 for chip select 1 for frequency set 0. Reset Source: ctl_amod_g_rst_n
  [15:8] PI_MR14_DATA_F0_1 — Data to program into memory mode register 14 for chip select 1 for frequency set 0. Reset Source: ctl_amod_g_rst_n
  [7:0] PI_MR12_DATA_F0_1 — Data to program into memory mode register 12 for chip select 1 for frequency set 0. Reset Source: ctl_amod_g_rst_n
{0x2000+4i} DDR16SS_CTLPHY_WRAP_CTL_CFG_CTLCFG_DENALI_PI_{i} (i=329..334)
  [16:0] PI_MR{i-329}_DATA_F1_1 — Data to program into memory mode register {i-329} for chip select 1 for frequency set 1. Reset Source: ctl_amod_g_rst_n
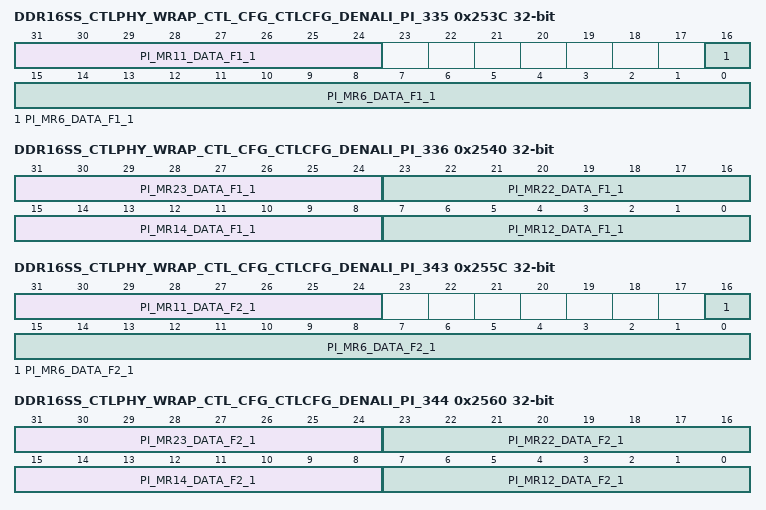
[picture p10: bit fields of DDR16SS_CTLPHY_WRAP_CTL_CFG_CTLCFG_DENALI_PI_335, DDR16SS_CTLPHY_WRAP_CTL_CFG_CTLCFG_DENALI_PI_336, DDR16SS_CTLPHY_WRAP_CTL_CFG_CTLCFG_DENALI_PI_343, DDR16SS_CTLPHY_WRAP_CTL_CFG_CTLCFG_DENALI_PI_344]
0x253C DDR16SS_CTLPHY_WRAP_CTL_CFG_CTLCFG_DENALI_PI_335
  [31:24] PI_MR11_DATA_F1_1 — Data to program into memory mode register 11 for chip select 1 for frequency set 1. Reset Source: ctl_amod_g_rst_n
  [16:0] PI_MR6_DATA_F1_1 — Data to program into memory mode register 6 for chip select 1 for frequency set 1. Reset Source: ctl_amod_g_rst_n
0x2540 DDR16SS_CTLPHY_WRAP_CTL_CFG_CTLCFG_DENALI_PI_336
  [31:24] PI_MR23_DATA_F1_1 — Data to program into memory mode register 23 for chip select 1 for frequency set 1. Reset Source: ctl_amod_g_rst_n
  [23:16] PI_MR22_DATA_F1_1 — Data to program into memory mode register 22 for chip select 1 for frequency set 1. Reset Source: ctl_amod_g_rst_n
  [15:8] PI_MR14_DATA_F1_1 — Data to program into memory mode register 14 for chip select 1 for frequency set 1. Reset Source: ctl_amod_g_rst_n
  [7:0] PI_MR12_DATA_F1_1 — Data to program into memory mode register 12 for chip select 1 for frequency set 1. Reset Source: ctl_amod_g_rst_n
{0x2000+4i} DDR16SS_CTLPHY_WRAP_CTL_CFG_CTLCFG_DENALI_PI_{i} (i=337..342)
  [16:0] PI_MR{i-337}_DATA_F2_1 — Data to program into memory mode register {i-337} for chip select 1 for frequency set 2. Reset Source: ctl_amod_g_rst_n
0x255C DDR16SS_CTLPHY_WRAP_CTL_CFG_CTLCFG_DENALI_PI_343
  [31:24] PI_MR11_DATA_F2_1 — Data to program into memory mode register 11 for chip select 1 for frequency set 2. Reset Source: ctl_amod_g_rst_n
  [16:0] PI_MR6_DATA_F2_1 — Data to program into memory mode register 6 for chip select 1 for frequency set 2. Reset Source: ctl_amod_g_rst_n
0x2560 DDR16SS_CTLPHY_WRAP_CTL_CFG_CTLCFG_DENALI_PI_344
  [31:24] PI_MR23_DATA_F2_1 — Data to program into memory mode register 23 for chip select 1 for frequency set 2. Reset Source: ctl_amod_g_rst_n
  [23:16] PI_MR22_DATA_F2_1 — Data to program into memory mode register 22 for chip select 1 for frequency set 2. Reset Source: ctl_amod_g_rst_n
  [15:8] PI_MR14_DATA_F2_1 — Data to program into memory mode register 14 for chip select 1 for frequency set 2. Reset Source: ctl_amod_g_rst_n
  [7:0] PI_MR12_DATA_F2_1 — Data to program into memory mode register 12 for chip select 1 for frequency set 2. Reset Source: ctl_amod_g_rst_n
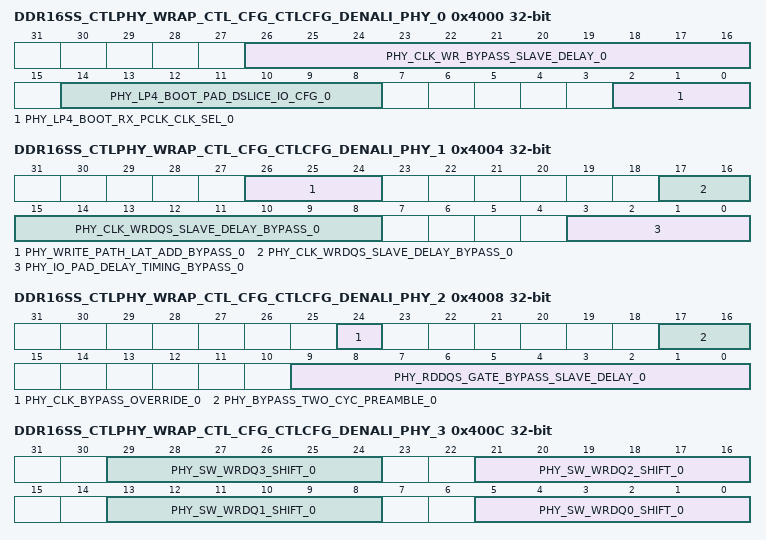
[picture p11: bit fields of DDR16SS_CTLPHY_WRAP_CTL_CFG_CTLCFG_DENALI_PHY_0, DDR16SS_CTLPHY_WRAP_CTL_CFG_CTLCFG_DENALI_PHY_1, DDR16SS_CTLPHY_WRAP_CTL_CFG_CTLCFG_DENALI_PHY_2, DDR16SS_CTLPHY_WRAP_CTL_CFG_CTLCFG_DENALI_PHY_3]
0x4000 DDR16SS_CTLPHY_WRAP_CTL_CFG_CTLCFG_DENALI_PHY_0
  [26:16] PHY_CLK_WR_BYPASS_SLAVE_DELAY_0 — Write data clock bypass mode target delay setting for slice 0. Reset Source: ctl_amod_g_rst_n
  [14:8] PHY_LP4_BOOT_PAD_DSLICE_IO_CFG_0 — Controls PCLK/PARK pin for pad for slice 0 with boot frequency. Reset Source: ctl_amod_g_rst_n
  [2:0] PHY_LP4_BOOT_RX_PCLK_CLK_SEL_0 — RX_PCLK boot clock frequency selection for slice 0. Reset Source: ctl_amod_g_rst_n
0x4004 DDR16SS_CTLPHY_WRAP_CTL_CFG_CTLCFG_DENALI_PHY_1
  [26:24] PHY_WRITE_PATH_LAT_ADD_BYPASS_0 — Number of cycles on bypass mode to delay the incoming dfi_wrdata_en/dfi_wrdata signals for slice 0. Reset Source: ctl_amod_g_rst_n
  [17:8] PHY_CLK_WRDQS_SLAVE_DELAY_BYPASS_0 — Write DQS bypass mode target delay setting for slice 0. Reset Source: ctl_amod_g_rst_n
  [3:0] PHY_IO_PAD_DELAY_TIMING_BYPASS_0 — Feedback pad's OPAD and IPAD delay timing on bypass mode for slice 0. Reset Source: ctl_amod_g_rst_n
0x4008 DDR16SS_CTLPHY_WRAP_CTL_CFG_CTLCFG_DENALI_PHY_2
  [24] PHY_CLK_BYPASS_OVERRIDE_0 — Bypass mode override setting for slice 0. Reset Source: ctl_amod_g_rst_n
  [17:16] PHY_BYPASS_TWO_CYC_PREAMBLE_0 — Two_cycle_preamble for bypass mode for slice 0. Reset Source: ctl_amod_g_rst_n
  [9:0] PHY_RDDQS_GATE_BYPASS_SLAVE_DELAY_0 — Read DQS bypass mode target delay setting for slice 0. Reset Source: ctl_amod_g_rst_n
0x400C DDR16SS_CTLPHY_WRAP_CTL_CFG_CTLCFG_DENALI_PHY_3
  [8n+5:8n] PHY_SW_WRDQ{n}_SHIFT_0 (n=0..3) — Manual override of automatic half_cycle_shift/cycle_shift for write DQ{n} for slice 0. Bit [0] enables override of half_cycle_shift. Bit [1] is the half_cycle_shift value. Bit [2] enables override of cycle shift. Bits [4:3] are the cycle_shift value. Reset Source: ctl_amod_g_rst_n
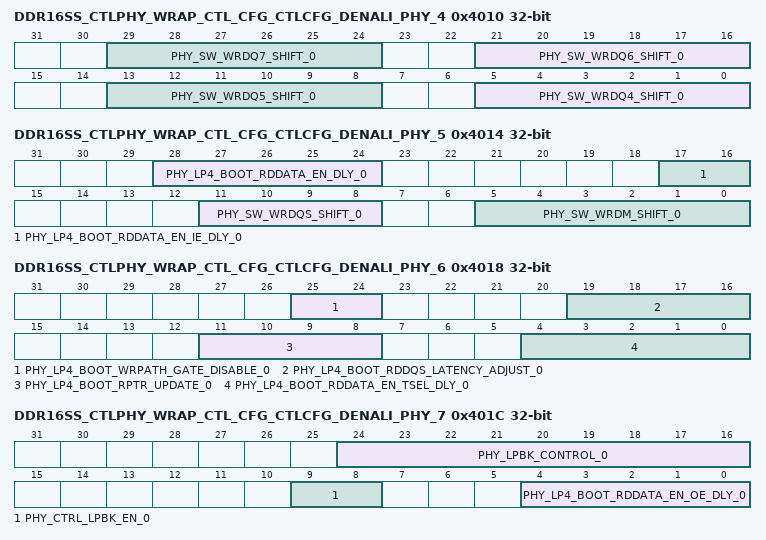
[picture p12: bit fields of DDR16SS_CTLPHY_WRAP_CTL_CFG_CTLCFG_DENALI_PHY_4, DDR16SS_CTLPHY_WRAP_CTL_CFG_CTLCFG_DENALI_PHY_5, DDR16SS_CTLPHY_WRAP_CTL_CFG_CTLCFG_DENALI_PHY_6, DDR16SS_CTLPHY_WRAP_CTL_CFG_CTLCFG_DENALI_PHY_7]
0x4010 DDR16SS_CTLPHY_WRAP_CTL_CFG_CTLCFG_DENALI_PHY_4
  [8n-27:8n-32] PHY_SW_WRDQ{n}_SHIFT_0 (n=4..7) — Manual override of automatic half_cycle_shift/cycle_shift for write DQ{n} for slice 0. Bit [0] enables override of half_cycle_shift. Bit [1] is the half_cycle_shift value. Bit [2] enables override of cycle shift. Bits [4:3] are the cycle_shift value. Reset Source: ctl_amod_g_rst_n
0x4014 DDR16SS_CTLPHY_WRAP_CTL_CFG_CTLCFG_DENALI_PHY_5
  [28:24] PHY_LP4_BOOT_RDDATA_EN_DLY_0 — For LPDDR4 boot frequency, the number of cycles that the dfi_rddata_en signal is early for slice 0. Reset Source: ctl_amod_g_rst_n
  [17:16] PHY_LP4_BOOT_RDDATA_EN_IE_DLY_0 — For LPDDR4 boot frequency, the number of cycles that the dfi_rddata_en signal is earlier than necessary for input enable generation for slice 0. Reset Source: ctl_amod_g_rst_n
  [11:8] PHY_SW_WRDQS_SHIFT_0 — Manual override of automatic half_cycle_shift/cycle_shift for write DQS for slice 0. Bit [0] enables override of half_cycle_shift. Bit [1] is the half_cycle_shift value. Bit [2] enables override of cycle shift. Bit [3] is the cycle_shift value. Reset Source: ctl_amod_g_rst_n
  [5:0] PHY_SW_WRDM_SHIFT_0 — Manual override of automatic half_cycle_shift/cycle_shift for write DM for slice 0. Bit [0] enables override of half_cycle_shift. Bit [1] is the half_cycle_shift value. Bit [2] enables override of cycle shift. Bits [4:3] are the cycle_shift value. Reset Source: ctl_amod_g_rst_n
0x4018 DDR16SS_CTLPHY_WRAP_CTL_CFG_CTLCFG_DENALI_PHY_6
  [25:24] PHY_LP4_BOOT_WRPATH_GATE_DISABLE_0 — For LPDDR4 boot frequency, write path clock gating disable for slice 0. Bit [0]: disable pull in wrdata_en; Bit [1]: disable write path clock gating, clock always on Reset Source: ctl_amod_g_rst_n
  [19:16] PHY_LP4_BOOT_RDDQS_LATENCY_ADJUST_0 — For LPDDR4 boot frequency, the number of cycles to delay the incoming dfi_rddata_en for read DQS gate generation for slice 0. Reset Source: ctl_amod_g_rst_n
  [11:8] PHY_LP4_BOOT_RPTR_UPDATE_0 — For LPDDR4 boot frequency, the offset in cycles from the dfi_rddata_en signal to releasing data from the entry FIFO for slice 0. Reset Source: ctl_amod_g_rst_n
  [4:0] PHY_LP4_BOOT_RDDATA_EN_TSEL_DLY_0 — For LPDDR4 boot frequency, the number of cycles that the dfi_rddata_en signal is earlier than necessary for TSEL enable generation for slice 0. Reset Source: ctl_amod_g_rst_n
0x401C DDR16SS_CTLPHY_WRAP_CTL_CFG_CTLCFG_DENALI_PHY_7
  [24:16] PHY_LPBK_CONTROL_0 — Loopback control bits for slice 0. Reset Source: ctl_amod_g_rst_n
  [9:8] PHY_CTRL_LPBK_EN_0 — Loopback control en for slice 0. Reset Source: ctl_amod_g_rst_n
  [4:0] PHY_LP4_BOOT_RDDATA_EN_OE_DLY_0 — For LPDDR4 boot frequency, the number of cycles that the dfi_rddata_en signal is earlier than necessary for extended OE generation for slice 0. Reset Source: ctl_amod_g_rst_n
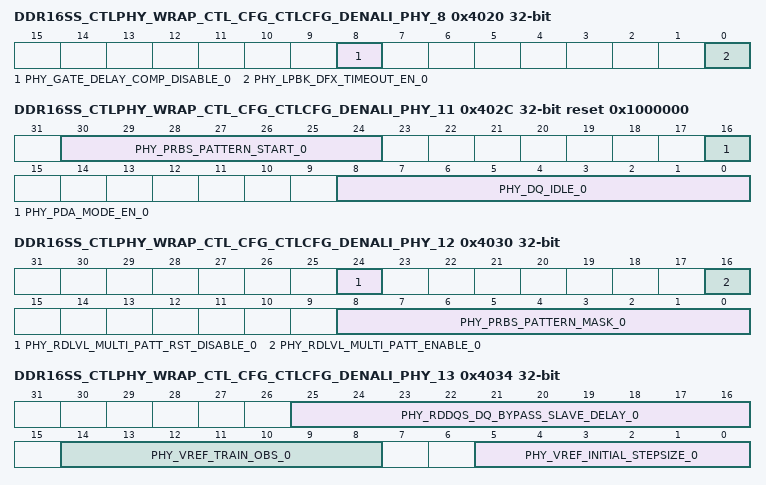
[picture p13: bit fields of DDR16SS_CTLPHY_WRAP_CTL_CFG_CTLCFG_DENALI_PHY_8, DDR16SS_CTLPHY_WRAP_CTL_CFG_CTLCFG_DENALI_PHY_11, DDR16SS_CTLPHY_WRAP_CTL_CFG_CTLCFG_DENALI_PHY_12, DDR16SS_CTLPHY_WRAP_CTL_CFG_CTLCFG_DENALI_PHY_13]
0x4020 DDR16SS_CTLPHY_WRAP_CTL_CFG_CTLCFG_DENALI_PHY_8
  [8] PHY_GATE_DELAY_COMP_DISABLE_0 — use the control whether to compensate half_cycle when gate_target_delay is larger than half_cycle for the gate close for slice 0. Reset Source: ctl_amod_g_rst_n
  [0] PHY_LPBK_DFX_TIMEOUT_EN_0 — Loopback read only test timeout mechanism enable for slice 0. Reset Source: ctl_amod_g_rst_n
0x4024 DDR16SS_CTLPHY_WRAP_CTL_CFG_CTLCFG_DENALI_PHY_9
  [31:0] PHY_AUTO_TIMING_MARGIN_CONTROL_0 — Auto timing marging control bits for slice 0. Reset Source: ctl_amod_g_rst_n
0x4028 DDR16SS_CTLPHY_WRAP_CTL_CFG_CTLCFG_DENALI_PHY_10 ro
  [27:0] PHY_AUTO_TIMING_MARGIN_OBS_0 — Observation register for the auto_timing_margin for slice 0. READ-ONLY Reset Source: ctl_amod_g_rst_n
0x402C DDR16SS_CTLPHY_WRAP_CTL_CFG_CTLCFG_DENALI_PHY_11 reset 0x1000000
  [30:24] PHY_PRBS_PATTERN_START_0 — PRBS7 start pattern for slice 0. Reset Source: ctl_amod_g_rst_n
  [16] PHY_PDA_MODE_EN_0 — When set to 1, the invalid DQs will be driven by the dfi_wrdata to make sure the tpda_s and tpda_h's timing is meet for slice 0. Reset Source: ctl_amod_g_rst_n
  [8:0] PHY_DQ_IDLE_0 — When set to 1, the inavlid DQ will be driven to high, when set to 0, the invalid DQ will be driven to low for slice 0. Reset Source: ctl_amod_g_rst_n
0x4030 DDR16SS_CTLPHY_WRAP_CTL_CFG_CTLCFG_DENALI_PHY_12
  [24] PHY_RDLVL_MULTI_PATT_RST_DISABLE_0 — Read Leveling read level windows disable reset for slice 0. Reset Source: ctl_amod_g_rst_n
  [16] PHY_RDLVL_MULTI_PATT_ENABLE_0 — Read Leveling Multi-pattern enable for slice 0. Reset Source: ctl_amod_g_rst_n
  [8:0] PHY_PRBS_PATTERN_MASK_0 — PRBS7 mask signal for slice 0. Reset Source: ctl_amod_g_rst_n
0x4034 DDR16SS_CTLPHY_WRAP_CTL_CFG_CTLCFG_DENALI_PHY_13 access per field
  [25:16] PHY_RDDQS_DQ_BYPASS_SLAVE_DELAY_0 rw — Read DQS data clock bypass mode target delay setting for slice 0. Reset Source: ctl_amod_g_rst_n
  [14:8] PHY_VREF_TRAIN_OBS_0 ro — Observation register for best vref value for slice 0. READ-ONLY Reset Source: ctl_amod_g_rst_n
  [5:0] PHY_VREF_INITIAL_STEPSIZE_0 rw — Data slice initial VREF training step size for slice 0. Reset Source: ctl_amod_g_rst_n
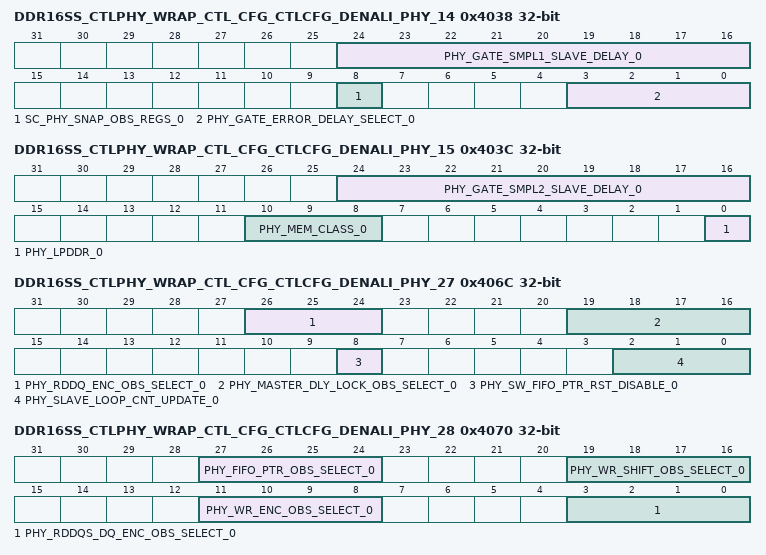
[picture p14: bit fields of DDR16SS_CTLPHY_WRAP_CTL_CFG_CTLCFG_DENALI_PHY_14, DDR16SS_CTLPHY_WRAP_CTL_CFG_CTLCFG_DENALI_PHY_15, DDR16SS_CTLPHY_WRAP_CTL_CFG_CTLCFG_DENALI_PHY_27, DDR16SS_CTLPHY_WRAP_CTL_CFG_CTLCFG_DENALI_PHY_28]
0x4038 DDR16SS_CTLPHY_WRAP_CTL_CFG_CTLCFG_DENALI_PHY_14 access per field
  [24:16] PHY_GATE_SMPL1_SLAVE_DELAY_0 rw — Number of cycles to delay the read DQS gate signal to generate gate1 signal for on-the-fly read DQS training for slice 0. Reset Source: ctl_amod_g_rst_n
  [8] SC_PHY_SNAP_OBS_REGS_0 wo — Initiates a snapshot of the internal observation registers for slice 0. Set to 1 to trigger. WRITE-ONLY Reset Source: ctl_amod_g_rst_n
  [3:0] PHY_GATE_ERROR_DELAY_SELECT_0 rw — Number of cycles to wait for the DQS gate to close before flagging an error for slice 0. Reset Source: ctl_amod_g_rst_n
0x403C DDR16SS_CTLPHY_WRAP_CTL_CFG_CTLCFG_DENALI_PHY_15
  [24:16] PHY_GATE_SMPL2_SLAVE_DELAY_0 — Number of cycles to delay the read DQS gate signal to generate gate2 signal for on-the-fly read DQS training for slice 0. Reset Source: ctl_amod_g_rst_n
  [10:8] PHY_MEM_CLASS_0 — Indicates the type of DRAM for slice 0. 0 for DDR3, 1 for DDR4, 2 for DDR5, 4 for LPDDR2, 5 for LPDDR3. 6 for LPDDR4 Reset Source: ctl_amod_g_rst_n
  [0] PHY_LPDDR_0 — Adds a cycle of delay for the slice 0 to match the address slice. Set to 1 to add a cycle Reset Source: ctl_amod_g_rst_n
0x4040 DDR16SS_CTLPHY_WRAP_CTL_CFG_CTLCFG_DENALI_PHY_16
  [1:0] ON_FLY_GATE_ADJUST_EN_0 — Control the on-the-fly gate adjustment for slice 0. Reset Source: ctl_amod_g_rst_n
0x4044 DDR16SS_CTLPHY_WRAP_CTL_CFG_CTLCFG_DENALI_PHY_17 ro
  [31:0] PHY_GATE_TRACKING_OBS_0 — Report the on-the-fly gate measurement result for slice 0. READ-ONLY Reset Source: ctl_amod_g_rst_n
0x4048 DDR16SS_CTLPHY_WRAP_CTL_CFG_CTLCFG_DENALI_PHY_18
  [1:0] PHY_LP4_PST_AMBLE_0 — Controls the read postamble extension for LPDDR4 for slice 0. Reset Source: ctl_amod_g_rst_n
{0x4000+4i} DDR16SS_CTLPHY_WRAP_CTL_CFG_CTLCFG_DENALI_PHY_{i} (i=19..26)
  [31:0] PHY_RDLVL_PATT{i-11}_0 — Read leveling pattern {i-11} data for slice 0. Reset Source: ctl_amod_g_rst_n
0x406C DDR16SS_CTLPHY_WRAP_CTL_CFG_CTLCFG_DENALI_PHY_27
  [26:24] PHY_RDDQ_ENC_OBS_SELECT_0 — Select value to map the internal read DQ target delay encoded settings to the accessible read DQ encoded target delay observation register for slice 0. Reset Source: ctl_amod_g_rst_n
  [19:16] PHY_MASTER_DLY_LOCK_OBS_SELECT_0 — Select value to map the internal master delay observation registers to the accessible master delay observation register for slice 0. Reset Source: ctl_amod_g_rst_n
  [8] PHY_SW_FIFO_PTR_RST_DISABLE_0 — Disables automatic reset of the read entry FIFO pointers for slice 0. Set to 1 to disable automatic resets. Reset Source: ctl_amod_g_rst_n
  [2:0] PHY_SLAVE_LOOP_CNT_UPDATE_0 — Reserved for future use for slice 0. Reset Source: ctl_amod_g_rst_n
0x4070 DDR16SS_CTLPHY_WRAP_CTL_CFG_CTLCFG_DENALI_PHY_28
  [27:24] PHY_FIFO_PTR_OBS_SELECT_0 — Select value to map the internal read entry FIFO read/write pointers to the accessible read entry FIFO pointer observation register for slice 0. Reset Source: ctl_amod_g_rst_n
  [19:16] PHY_WR_SHIFT_OBS_SELECT_0 — Select value to map the internal write DQ/DQS automatic cycle/half_cycle shift settings to the accessible write DQ/DQS shift observation register for slice 0. Reset Source: ctl_amod_g_rst_n
  [11:8] PHY_WR_ENC_OBS_SELECT_0 — Select value to map the internal write DQ target delay encoded settings to the accessible write DQ encoded target delay observation register for slice 0. Reset Source: ctl_amod_g_rst_n
  [3:0] PHY_RDDQS_DQ_ENC_OBS_SELECT_0 — Select value to map the internal read DQS DQ rise/fall target delay encoded settings to the accessible read DQS DQ rise/fall encoded target delay observation registers for slice 0. Reset Source: ctl_amod_g_rst_n
0x4074 DDR16SS_CTLPHY_WRAP_CTL_CFG_CTLCFG_DENALI_PHY_29 access per field
  [29:24] PHY_WRLVL_CAPTURE_CNT_0 rw — Number of samples to take at each DQS target delay setting during write leveling for slice 0. Reset Source: ctl_amod_g_rst_n
  [17:16] PHY_WRLVL_ALGO_0 rw — Write leveling algorithm selection for slice 0. Reset Source: ctl_amod_g_rst_n
  [8] SC_PHY_LVL_DEBUG_CONT_0 wo — Allows the leveling state machine to advance [when in debug mode] for slice 0. Set to 1 to trigger. WRITE-ONLY Reset Source: ctl_amod_g_rst_n
  [0] PHY_LVL_DEBUG_MODE_0 rw — Enables leveling debug mode for slice 0. Set to 1 to enable. Reset Source: ctl_amod_g_rst_n
0x4078 DDR16SS_CTLPHY_WRAP_CTL_CFG_CTLCFG_DENALI_PHY_30
  [27:24] PHY_GTLVL_UPDT_WAIT_CNT_0 — Number of cycles + 4 to wait after changing DQS target delay setting during gate training for slice 0. The valid range is 0x0 to 0xB. Reset Source: ctl_amod_g_rst_n
  [21:16] PHY_GTLVL_CAPTURE_CNT_0 — Number of samples to take at each DQS target delay setting during gate training for slice 0. Reset Source: ctl_amod_g_rst_n
  [15:8] PHY_DQ_MASK_0 — For ECC slice, should set this register to do DQ bit mask for slice 0. Reset Source: ctl_amod_g_rst_n
  [3:0] PHY_WRLVL_UPDT_WAIT_CNT_0 — Number of cycles to wait after changing DQS target delay setting during write leveling for slice 0. Reset Source: ctl_amod_g_rst_n
0x407C DDR16SS_CTLPHY_WRAP_CTL_CFG_CTLCFG_DENALI_PHY_31
  [28:24] PHY_RDLVL_RDDQS_DQ_OBS_SELECT_0 — Select value to map an individual DQ data window leading/trailing edge to the leading/trailing edge observation registers during read leveling for slice 0. Reset Source: ctl_amod_g_rst_n
  [17:16] PHY_RDLVL_OP_MODE_0 — Read leveling algorithm select for slice 0. Clear to 0 to move linearly from left to right. Set to 1 to start inside the window, move left and then move right. Reset Source: ctl_amod_g_rst_n
  [11:8] PHY_RDLVL_UPDT_WAIT_CNT_0 — Number of cycles to wait after changing DQS target delay setting during read leveling for slice 0. Reset Source: ctl_amod_g_rst_n
  [5:0] PHY_RDLVL_CAPTURE_CNT_0 — Number of samples to take at each DQS target delay setting during read leveling for slice 0. Reset Source: ctl_amod_g_rst_n
